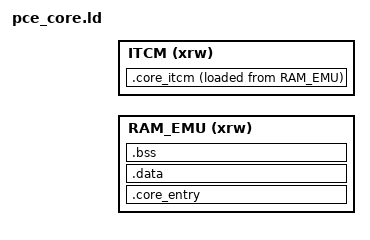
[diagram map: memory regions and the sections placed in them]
/*
 * PC Engine / PC Engine CD core linker script — same split as firmware
 * cores/pce/pce_core.ld (ITCM: gfx, h6280, pce, sound, cd, scsi, adpcm;
 * main_pce.o stays in RAM_EMU). Object paths match BUILD_DIR=build/core.
 */

INCLUDE gnw_ram_emu.ld
INCLUDE gnw_itcm_core.ld

MEMORY
{
  RAM_EMU (xrw) : ORIGIN = __RAM_EMU_START__, LENGTH = __RAM_EMU_LENGTH__
  ITCM    (xrw) : ORIGIN = __ITCM_CORE_START__, LENGTH = __ITCM_CORE_LENGTH__
}

SECTIONS
{
  .core_entry __RAM_EMU_START__ :
  {
    KEEP(*(.core_entry))
    KEEP(*(.gw_core_bridge_probe))
    . = ALIGN(4);
    EXCLUDE_FILE(
      build/core/gfx.o
      build/core/h6280.o
      build/core/pce.o
      build/core/sound_pce.o
      build/core/pce_cd.o
      build/core/pce_scsi.o
      build/core/pce_adpcm.o
    ) *(.text*)
    *(.rodata*)
    *(.glue_7)
    *(.glue_7t)

    . = ALIGN(4);
    __CORE_INIT_ARRAY_START__ = .;
    KEEP(*(SORT(.init_array.*)))
    KEEP(*(.init_array*))
    __CORE_INIT_ARRAY_END__ = .;
  } >RAM_EMU

  . = ALIGN(8);
  .data :
  {
    *(.data*)
  } >RAM_EMU

  __CORE_CODE_END__ = .;

  . = ALIGN(8);
  .bss (NOLOAD) :
  {
    *(.bss*)
    *(COMMON)
  } >RAM_EMU

  __CORE_BSS_END__ = .;

  ASSERT(__CORE_BSS_END__ <= __RAM_EMU_END__,
         "Error: PCE core RAM_EMU segment (code+data+bss) overflows RAM_EMU")

  .core_itcm __ITCM_CORE_START__ :
  {
    __CORE_ITCM_CODE_START__ = .;
    build/core/gfx.o(.text*)
    build/core/h6280.o(.text*)
    build/core/pce.o(.text*)
    build/core/sound_pce.o(.text*)
    build/core/pce_cd.o(.text*)
    build/core/pce_scsi.o(.text*)
    build/core/pce_adpcm.o(.text*)
    . = ALIGN(4);
    __CORE_ITCM_CODE_END__ = .;
  } >ITCM AT>RAM_EMU

  __CORE_ITCM_BSS_END__ = __CORE_ITCM_CODE_END__;

  ASSERT(__CORE_ITCM_BSS_END__ <= __ITCM_CORE_START__ + __ITCM_CORE_LENGTH__,
         "Error: PCE core ITCM segment (code) overflows the 64K ITCM region")

  /DISCARD/ :
  {
    *(.fini_array*)
    *(.preinit_array*)
    *(.ARM.exidx*)
    *(.ARM.extab*)
    *(.comment)
    *(.ARM.attributes)
  }
}
